# CC27x0 register map
File version: 1.0
CPU: CM4 r0p4, little endian, no MPU, no FPU, VTOR, 3 interrupt priority bits
Registers are 32-bit, read-write, reset 0x0 unless marked. A register's access mark holds for its fields unless they carry their own. Offsets are from the block's base; [hi:lo] are bit positions; {n}, {i} and the like mark numbered series; 'fields as' and 'values as' point back to an identical list.

## CKMD — Clock Controller
Base 0x40001000
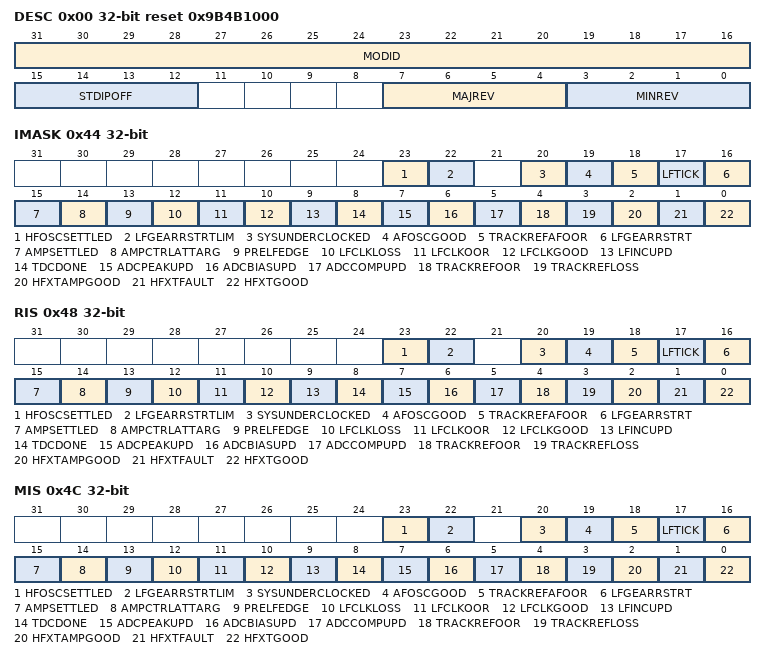
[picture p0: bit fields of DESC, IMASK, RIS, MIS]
0x00 DESC ro reset 0x9B4B1000 — IP Description
  [31:16] MODID — Module identifier
  [15:12] STDIPOFF — Standard IP MMR block offset
  [7:4] MAJREV — Major revision
  [3:0] MINREV — Minor revision
0x44 IMASK — Interrupt mask. This register selects interrupt sources which are allowed to pass from RIS to MIS when the corresponding bit-fields are set to 1.
  [23] HFOSCSETTLED — Indicates that HFOSC has settled, based on LOOPCFG.SETTLED_TARGET and LOOPCFG1.SETTLEIRQ
  [22] LFGEARRSTRTLIM — Indicates that the LFINC filter gearing mechanism has restarted more than LFINCCTL2.GEARRSTRTLIM
  [20] SYSUNDERCLOCKED — Indicates system frequency has been lowered. It will be set only if HFTRACKCTL.UNDERCLK is appropriately configured and HFOSC tracking loop is not running.
  [19] AFOSCGOOD — AFOSC good indication.
  [18] TRACKREFAFOOR — Out-of-range indication from the AFOSC tracking loop. Indicates that the reference clock frequency of AFOSC tracking loop is out-of-range.
  [17] LFTICK — 32kHz TICK to RTC and WDT. Either derived from selected LFCLK or generated from CLKULL in absence of LFCLK.
  [16] LFGEARRSTRT — LFINC filter gearing restart. Indicates that the LFINC filter restarted gearing. Subsequent LFINC estimates may have higher variation.
  [15] AMPSETTLED — HFXT Amplitude compensation - settled Indicates that the amplitude compensation FSM has reached the SETTLED or TCXOMODE state, and the controls configured in HFXTTARG or HFXTDYN are reached.
  [14] AMPCTRLATTARG — HFXT Amplitude compensation - controls at target Indicates that the control values configured in HFXTTARG or HFXTDYN are reached. Applies to Q1CAP, Q2CAP and IREF.
  [13] PRELFEDGE — Pre-LF clock edge detect. Indicates that a positive edge occured on the selected pre-LF clock CLKSEL.PRELFCLK' Can be used by software to confirm that a LF clock source is running and within the expected frequency, before selecting it as the main LF clock source.
  [12] LFCLKLOSS — LF clock is lost. Indicates that no LF clock edge occured for ~49us (~1.6 times nominal period). The system will automatically fall-back to generating LFTICK based on CLKULL, to avoid timing corruption. Note that this signal is NOT related to the analog LF clock-loss detector which can reset the device during STANDBY.
  [11] LFCLKOOR — LF clock period out-of-range. Indicates that a LF clock period was measured to be out-of-range, according to LFQUALCTL.MAXERR.
  [10] LFCLKGOOD — LF clock good. Indicates that the LF clock is good, according to the configuration in LFQUALCTL.
  [9] LFINCUPD — LFINC updated. Indicates that a new LFINC measurement value is available in LFCLKSTAT.LFINC.
  [8] TDCDONE — TDC done event. Indicates that the TDC measurement is done.
  [7] ADCPEAKUPD — HFXT-ADC PEAK measurement update event. Indicates that the HFXT-ADC PEAK measurement is done.
  [6] ADCBIASUPD — HFXT-ADC BIAS measurement update event. Indicates that the HFXT-ADC BIAS measurement is done.
  [5] ADCCOMPUPD — HFXT-ADC comparison update event. Indicates that the HFXT-ADC comparison is done.
  [4] TRACKREFOOR — Out-of-range indication from the tracking loop. Indicates that the selected reference clock frequency of the tracking loop is out-of-range.
  [3] TRACKREFLOSS — Clock loss indication from the tracking loop. Indicates that the selected reference clock of the tracking loop is lost.
  [2] HFXTAMPGOOD — HFXT amplitude good indication.
  [1] HFXTFAULT — HFXT fault indication. Indicates that HFXT did not start correctly, or its frequency is too low. HFXT will not recover from this fault and has to be restarted. This is only a one-time check at HFXT startup.
  [0] HFXTGOOD — HFXT good indication. Indicates that HFXT started correctly. The frequency is not necessarily good enough for radio operation. This is only a one-time check at HFXT startup.
0x48 RIS ro — Raw interrupt flag register
  fields as IMASK
0x4C MIS ro — Masked interrupt flag register
  fields as IMASK
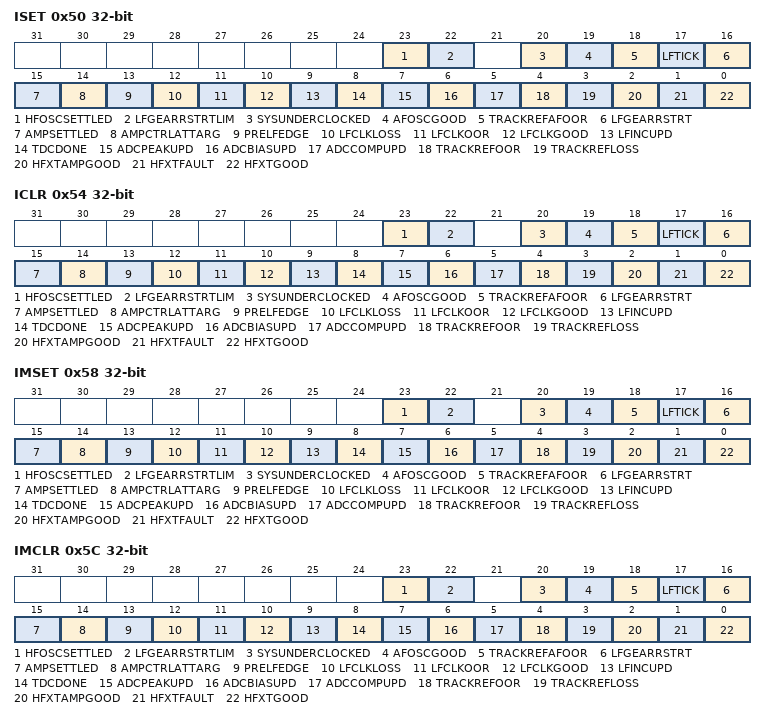
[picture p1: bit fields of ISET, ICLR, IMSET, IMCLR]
0x50 ISET wo — Interrupt flag set register
  fields as IMASK
0x54 ICLR wo — Interrupt flag clear register
  fields as IMASK
0x58 IMSET wo — Interrupt mask set register
  fields as IMASK
0x5C IMCLR wo — Interrupt mask clear register. Writing a 1 to a bit in this register will clear the corresponding IMASK bit.
  fields as IMASK
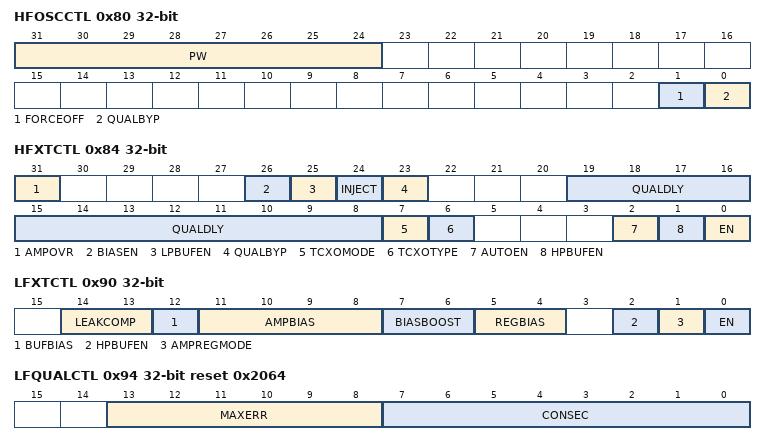
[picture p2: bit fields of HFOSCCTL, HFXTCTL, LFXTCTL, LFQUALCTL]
0x80 HFOSCCTL — Internal. Only to be used through TI provided API.
  [31:24] PW wo — Internal. Only to be used through TI provided API.
  [1] FORCEOFF — Internal. Only to be used through TI provided API.
  [0] QUALBYP — Internal. Only to be used through TI provided API.
0x84 HFXTCTL — High frequency crystal control
  [31] AMPOVR — Internal. Only to be used through TI provided API.
  [26] BIASEN — Internal. Only to be used through TI provided API.
  [25] LPBUFEN — Internal. Only to be used through TI provided API.
  [24] INJECT — Internal. Only to be used through TI provided API.
  [23] QUALBYP — Internal. Only to be used through TI provided API.
  [19:8] QUALDLY — Skip potentially unstable clock cycles after enabling HFXT. Number of cycles skipped is 8*QUALDLY.
  [7] TCXOMODE — Temperature compensated crystal oscillator mode. Set this bit if a TXCO is connected.
  [6] TCXOTYPE — Type of temperature compensated crystal used. Only has effect if TCXOMODE is set.
    1=CMOS (Use with CMOS TCXO); 0=CLIPPEDSINE (Use with clipped-sine TCXO)
  [2] AUTOEN — Internal. Only to be used through TI provided API.
  [1] HPBUFEN — High performance clock buffer enable. This bit controls the clock output for the RF PLL. It is required for radio operation.
  [0] EN — Internal. Only to be used through TI provided API.
0x8C LFOSCCTL — Low frequency oscillator control
  [0] EN — LFOSC enable
0x90 LFXTCTL — Low frequency crystal control
  [14:13] LEAKCOMP — Leakage compensation control
    3=OFF (No leakage compensation); 1=HALF (Half leakage compensation); 0=FULL (Full leakage compensation)
  [12] BUFBIAS — Control the BIAS current of the input amp in LP buffer
    1=MAX (Maximum bias current: 50nA); 0=MIN (Minimum bias current: 25nA)
  [11:8] AMPBIAS — Adjust current mirror ratio into oscillator core. This value is depending on crystal and is set by FW. This field uses a 2's complement encoding.
  [7:6] BIASBOOST — Boost oscillator amplitude This value depends on the crystal and needs to be configured by Firmware.
  [5:4] REGBIAS — Regulation loop bias resistor value This value depends on the crystal and needs to be configured by Firmware.
  [2] HPBUFEN — Control the buffer used. In normal operation, low-power buffer is used in all device modes. The high-performance buffer is only used for test purposes.
  [1] AMPREGMODE — Amplitude regulation mode
    1=LOOPDIS (Amplitude control loop disabled); 0=LOOPEN (Amplitude control loop enabled)
  [0] EN — LFXT enable
0x94 LFQUALCTL reset 0x2064 — Low frequency clock qualification control
  [13:8] MAXERR — Maximum LFCLK period error. Value given in microseconds, 3 integer bits + 3 fractional bits.
  [7:0] CONSEC — Number of consecutive times the LFCLK period error has to be smaller than MAXERR to be considered "good". Setting this value to 0 will bypass clock qualification, and the "good" indicator will always be 1.
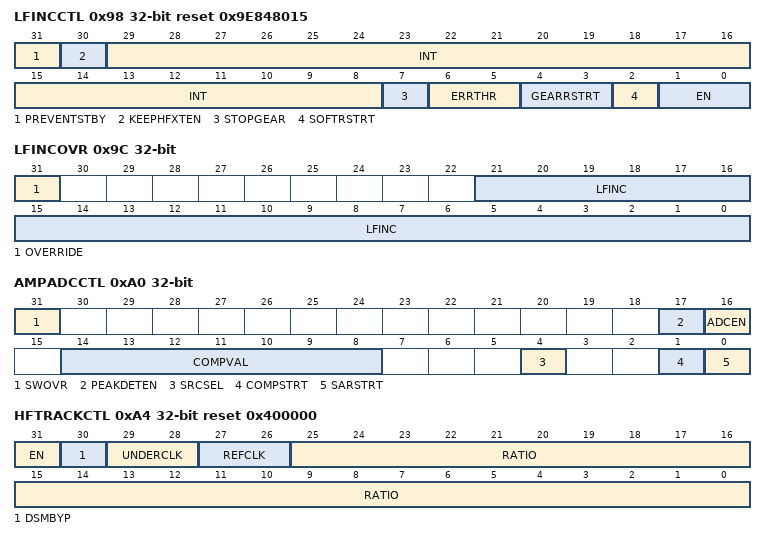
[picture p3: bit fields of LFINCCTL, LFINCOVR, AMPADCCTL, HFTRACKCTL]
0x98 LFINCCTL reset 0x9E848015 — Low frequency time increment control
  [31] PREVENTSTBY — Controls if the LFINC filter prevents STANBY entry until settled.
    1=ON (Enable. Prevent STANDBY entry.); 0=OFF (Disable. Do not prevent STANDBY entry.)
  [30] KEEPHFXTEN — Keeps the HFXT enabled till the LFINC filter settles
    1=EN (Enable. Keep HFXT enabled.); 0=DIS (Disable. Do not keep HFXT enabled.)
  [29:8] INT — Integral part of the LFINC filter. This value is updated by Hardware to reflect the current state of the filter. It can also be written to change the current state.
  [7] STOPGEAR — Controls the final gear of the LFINC filter.
    1=HIGH (The LF filter is considered settled when LFCLKSTAT2.MAINGEAR reads 8 and LFCLKSTAT2.SUBGEAR reads 7. That means the LF filter will take 71 LF periods to settle provided the gear does not restarts.); 0=LOW (The LF filter is considered settled when LFCLKSTAT2.MAINGEAR reads 9 and LFCLKSTAT2.SUBGEAR reads 7. That means the LF filter will take 79 LF periods to settle provided the gear does not restarts.)
  [6:5] ERRTHR — Controls the threshold for gearing restart of the LFINC filter. Only effective if GEARRSTRT is not ONETHR or TWOTHR.
    3=SMALL (Restart gearing on small error. Potentially more false restarts, faster response on small frequency shifts.); 2=MIDSMALL (Middle value towards SMALL.); 1=MIDLARGE (Middle value towards LARGE.); 0=LARGE (Restart gearing on large error. Fewer false restarts, slower response on small frequency shifts.)
  [4:3] GEARRSTRT — Controls gearing restart of the LFINC filter.
    2=TWOTHR (Restart gearing when the error accumulator crosses the threshold twice in a row.); 1=ONETHR (Restart gearing when the error accumulator crosses the threshold once.); 0=NEVER (Never restart gearing. Very stable filter value, but very slow response on frequency changes.)
  [2] SOFTRSTRT — Use a higher gear after re-enabling / wakeup. The filter will require 16-24 LFCLK periods to settle (depending on STOPGEAR), but may respond faster to frequency changes during STANDBY.
    1=ON (Use soft gearing restarts); 0=OFF (Don't use soft gearing restarts)
  [1:0] EN — Enable LFINC filter. Programming with a value of 0x3 will disable the LFINC filter
    2=AUTO (Enable based on HFOS getting settled. HFOSC gets settled after the tracking loop has updated equal to or more than LOOPCFG.SETTLED_TARGET times.); 1=EN (ENABLED); 0=DIS (DISABLED)
0x9C LFINCOVR — Low frequency time increment override control
  [31] OVERRIDE — Override LF increment Use the value provided in LFINC instead of the value calculated by Hardware.
  [21:0] LFINC — LF increment value This value is used when OVERRIDE is set to 1. Otherwise the value is calculated automatically. The current LFINC value can be read from [CKM.LFCLKSTAT.LFINC].
0xA0 AMPADCCTL — Internal. Only to be used through TI provided API.
  [31] SWOVR — Internal. Only to be used through TI provided API.
  [17] PEAKDETEN — Internal. Only to be used through TI provided API.
    1=ENABLE (Internal. Only to be used through TI provided API.); 0=DISABLE (Internal. Only to be used through TI provided API.)
  [16] ADCEN — Internal. Only to be used through TI provided API.
    values as PEAKDETEN
  [14:8] COMPVAL — Internal. Only to be used through TI provided API.
  [4] SRCSEL — Internal. Only to be used through TI provided API.
    1=PEAK (Internal. Only to be used through TI provided API.); 0=BIAS (Internal. Only to be used through TI provided API.)
  [1] COMPSTRT — Internal. Only to be used through TI provided API.
  [0] SARSTRT — Internal. Only to be used through TI provided API.
0xA4 HFTRACKCTL reset 0x400000 — High frequency tracking loop control
  [31] EN — Enable tracking loop.
  [30] DSMBYP — Bypass Delta-Sigma-Modulation of fine trim.
  [29:28] UNDERCLK — When the HFOSC tracking loop is not running, this bitfield can be used to set the condition to automatically lower the HFOSC frequency. This will prevent frequency drift that may lead to SOC instability.
    3=BOTH (Temperature event from Batmon or Timer event); 2=BATMON (Temperature event from Batmon); 1=TIMER (Timer event); 0=DIS (Disable)
  [27:26] REFCLK — Select the reference clock for the tracking loop. Change only while the tracking loop is disabled.
    2=GPI (Select GPI as reference clock.); 1=LRF (Select LRF reference clock.); 0=HFXT (Select HFXT as reference clock.)
  [25:0] RATIO — Reference clock ratio. Ratio format is 2b.24b RATIO = 24MHz / (2*reference-frequency) * 2^24 Commonly used reference clock frequencies are provided as enumerations.
    0x3000000=REF4M (Use for 4MHz reference clock); 0x1800000=REF8M (Use for 8MHz Reference clock); 0x400000=REF48M (Use for 48MHz reference clock)
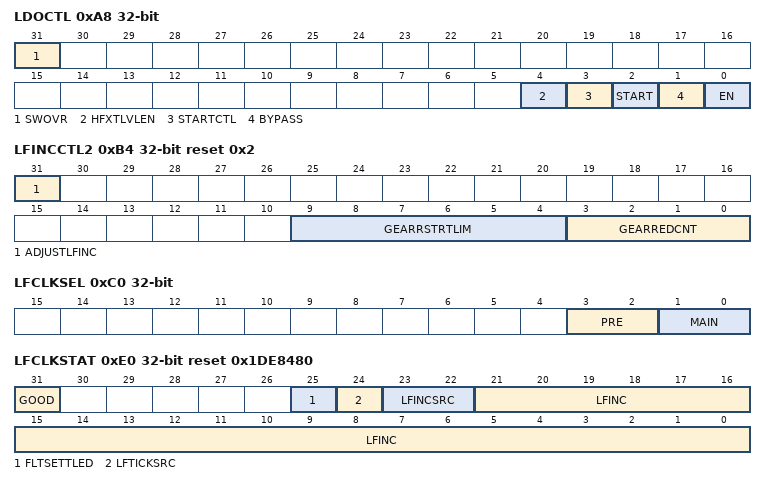
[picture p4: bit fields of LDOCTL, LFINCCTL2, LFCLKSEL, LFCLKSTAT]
0xA8 LDOCTL — Internal. Only to be used through TI provided API.
  [31] SWOVR — Internal. Only to be used through TI provided API.
  [4] HFXTLVLEN — Internal. Only to be used through TI provided API.
  [3] STARTCTL — Internal. Only to be used through TI provided API.
  [2] START — Internal. Only to be used through TI provided API.
  [1] BYPASS — Internal. Only to be used through TI provided API.
  [0] EN — Internal. Only to be used through TI provided API.
0xAC NABIASCTL — Nanoamp-bias control
  [0] EN — Enable nanoamp-bias
0xB0 LFMONCTL — Low-frequency clock-monitor control
  [0] EN — Enable LFMONITOR. Enable only after a LF clock source has been selected, enabled and is stable. If LFMONITOR detects a clock loss, the system will be reset.
0xB4 LFINCCTL2 reset 0x2 — Low frequency time increment control-2
  [31] ADJUSTLFINC — Adjusts LFINC while transitioning from fake to real LF clock if necessary. For the adjustment to happen, tracking loop must be running.
  [9:4] GEARRSTRTLIM — Specifies the number of times gear could be restarted before raising an interrupt. It has no impact on the number of times gear can be reduced. A value of 0 indicates that the interrupt mechanism is disabled
  [3:0] GEARREDCNT — Specifies the number by which gear should be reduced post standby exit
0xC0 LFCLKSEL — Low frequency clock selection
  [3:2] PRE — Select low frequency clock source for the PRELFCLK interrupt. Can be used by Software to confirm that the clock is running and it's frequency is good, before selecting it in MAIN.
    3=EXTLF (External LF clock through GPI.); 2=LFXT (Low frequency crystal oscillator); 1=LFOSC (Low frequency on-chip oscillator); 0=NONE (No clock. Output will be tied low.)
  [1:0] MAIN — Select the main low frequency clock source. If running, this clock will be used to generate LFTICK and as CLKULL during STANDBY. If not running, LFTICK will be generated from HFOSC and STANDBY entry will be prevented.
    3=EXTLF (External LF clock through GPI.); 2=LFXT (Low frequency crystal oscillator); 1=LFOSC (Low frequency on-chip oscillator); 0=FAKE (No LF clock selected. LFTICK will be generated from HFOSC, STANDBY entry will be prevented.)
0xC4 TDCCLKSEL — Internal. Only to be used through TI provided API.
  [2:0] REFCLK
    5=HFXT (Internal. Only to be used through TI provided API.); 4=AFOSC (Internal. Only to be used through TI provided API.); 3=GPI (Internal. Only to be used through TI provided API.); 2=CLKULL (Internal. Only to be used through TI provided API.); 1=CLKSVT (Internal. Only to be used through TI provided API.); 0=NONE (Internal. Only to be used through TI provided API.)
0xC8 ADCCLKSEL — ADC clock selection
  [1:0] SRC — Select ADC clock source Change only while ADC is disabled!
    1=HFXT (48MHz HFXT); 0=CLKSVT (48MHz CLKSVT)
0xE0 LFCLKSTAT ro reset 0x1DE8480 — Low-frequency clock status
  [31] GOOD — Low frequency clock good Note: This is only a coarse frequency check based on LFQUALCTL. The clock may not be accurate enough for timing purposes.
  [25] FLTSETTLED — LFINC filter is running and settled.
  [24] LFTICKSRC — Source of LFTICK.
    1=FAKE (LFTICK generated from CLKULL (LFCLK not available)); 0=LFCLK (LFTICK generated from the selected LFCLK)
  [23:22] LFINCSRC — Source of LFINC used by the RTC. This value depends on LFINCOVR.OVERRIDE, LF clock availability, HF tracking loop status and the device state (ACTIVE/STANDBY).
    3=FAKE (Using FAKE LFTICKs with corresponding LFINC value.); 2=OVERRIDE (Using override value from LFINCOVR.LFINC); 1=AVG (Using filtered / average value. This value is updated by hardware and can be read and updated in LFINCCTL.INT.); 0=MEAS (Using measured value. This value is updated by hardware and can be read from LFINC.)
  [21:0] LFINC — Measured value of LFINC. Given in microseconds with 16 fractional bits. This value is calculated by Hardware. It is the LFCLK period according to CLKULL cycles.
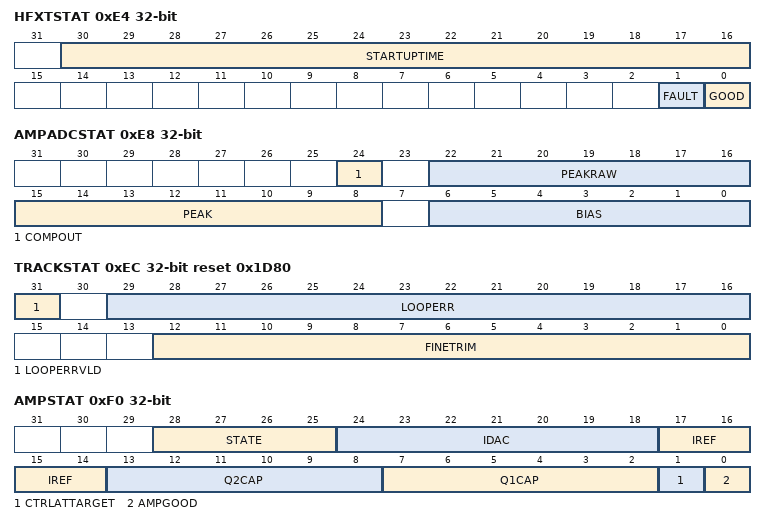
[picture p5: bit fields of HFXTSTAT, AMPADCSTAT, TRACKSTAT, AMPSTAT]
0xE4 HFXTSTAT ro — HFXT status information
  [30:16] STARTUPTIME — HFXT startup time Can be used by software to plan starting HFXT ahead in time. Measured whenever HFXT is enabled in CLKULL periods (24MHz), from HFXTCTL.EN until the clock is good for radio operation (amplitude compensation is settled).
  [1] FAULT — HFXT clock fault Indicates a lower than expected HFXT frequency. HFXT will not recover from this fault, disabling and re-enabling HFXT is required.
  [0] GOOD — HFXT clock available. The frequency is not necessarily good enough for radio operation.
0xE8 AMPADCSTAT ro — Internal. Only to be used through TI provided API.
  [24] COMPOUT — Internal. Only to be used through TI provided API.
  [22:16] PEAKRAW — Internal. Only to be used through TI provided API.
  [15:8] PEAK — Internal. Only to be used through TI provided API.
  [6:0] BIAS — Internal. Only to be used through TI provided API.
0xEC TRACKSTAT reset 0x1D80 — HF tracking loop status information
  [31] LOOPERRVLD ro — Current HFOSC tracking error valid This bit is one if the tracking loop is running and the error value is valid.
  [29:16] LOOPERR ro — Current HFOSC tracking error This field uses the internal fractional representation (sign, 9 integer bits, 4 fractional bits).
  [12:0] FINETRIM ro — Current HFOSC Fine-trim value This field uses the internal fractional representation (sign, 5 integer bits, 7 fractional bits). The actual trim value applied to the oscillator is delta-sigma modulated 6 bits non-signed (inverted sign bit + integer bits).
0xF0 AMPSTAT ro — HFXT Amplitude Compensation Status
  [28:25] STATE — Current AMPCOMP FSM state.
    15=SETTLED (Settled state); 14=UPDATEUP (Amplitude up correction); 12=TXCOMODE (TCXO settled state); 10=SHUTDN0 (First shutdown state); 7=INJWAIT (Post injection settle wait); 6=UPDATEDN (Amplitude down correction); 5=RAMP0 (Initial amplitude ramping with HFXTINIT values); 4=RAMP1 (Transition to HFXTTARG values); 3=INJECT (Injecting HFOSC for fast startup); 2=SHUTDN1 (Second shutdown state); 1=LDOSTART (Starting LDO); 0=IDLE (FSM in idle state)
  [24:18] IDAC — Current IDAC control value.
  [17:14] IREF — Current IREF control value.
  [13:8] Q2CAP — Current Q2CAP control value.
  [7:2] Q1CAP — Current Q1CAP control value.
  [1] CTRLATTARGET — HFXT control values match target values. This applies to IREF, Q1CAP, Q2CAP values.
  [0] AMPGOOD — HFXT amplitude good
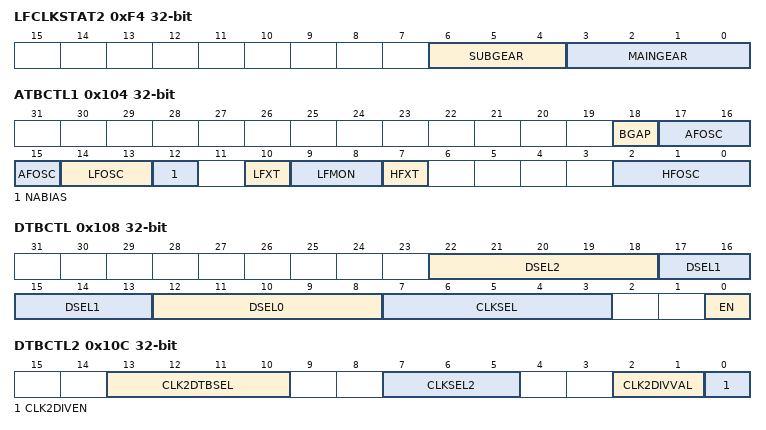
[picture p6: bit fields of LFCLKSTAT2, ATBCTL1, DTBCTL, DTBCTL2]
0xF4 LFCLKSTAT2 ro — Low-frequency clock status-2
  [6:4] SUBGEAR — The value of sub gear in LF filter. It counts from 0 to 7.
  [3:0] MAINGEAR — The value of main gear in LF filter. The main gear increments when the sub gear crosses 7.
0x100 ATBCTL0 — Internal. Only to be used through TI provided API.
  [23:0] SEL
    0x90000=AFOSCTESTCLK (Internal. Only to be used through TI provided API.); 0x70000=LFXTTESTCLK (Internal. Only to be used through TI provided API.); 0x50000=LFOSCTESTCLK (Internal. Only to be used through TI provided API.); 0x30000=HFXTTESTCLK (Internal. Only to be used through TI provided API.); 0x10000=HFOSCTESTCLK (Internal. Only to be used through TI provided API.); 0x4000=AFOSCOUT (Internal. Only to be used through TI provided API.); 0x1000=LFMONVTEST (Internal. Only to be used through TI provided API.); 0x100=HFOSCOUT (Internal. Only to be used through TI provided API.); 128=NABIASITEST (Internal. Only to be used through TI provided API.); 64=ADCDACOUT (Internal. Only to be used through TI provided API.); 32=ADCCOMPIN (Internal. Only to be used through TI provided API.); 16=ADCCOMPOUT (Internal. Only to be used through TI provided API.); 8=LFXTANA (Internal. Only to be used through TI provided API.); 2=VDDCKM (Internal. Only to be used through TI provided API.); 1=HFXTANA (Internal. Only to be used through TI provided API.); 0=OFF (Internal. Only to be used through TI provided API.)
0x104 ATBCTL1 — Internal. Only to be used through TI provided API.
  [18] BGAP — Internal. Only to be used through TI provided API.
  [17:15] AFOSC — Internal. Only to be used through TI provided API.
  [14:13] LFOSC — Internal. Only to be used through TI provided API.
    3=BOTH (Internal. Only to be used through TI provided API.); 2=VDDLOCAL (Internal. Only to be used through TI provided API.); 1=TESTCLK (Internal. Only to be used through TI provided API.); 0=OFF (Internal. Only to be used through TI provided API.)
  [12] NABIAS — Internal. Only to be used through TI provided API.
  [10] LFXT — Internal. Only to be used through TI provided API.
    1=TESTCLK (Internal. Only to be used through TI provided API.); 0=OFF (Internal. Only to be used through TI provided API.)
  [9:8] LFMON — Internal. Only to be used through TI provided API.
    2=TEST2 (Internal. Only to be used through TI provided API.); 1=TEST1 (Internal. Only to be used through TI provided API.); 0=OFF (Internal. Only to be used through TI provided API.)
  [7] HFXT — Internal. Only to be used through TI provided API.
  [2:0] HFOSC — Internal. Only to be used through TI provided API.
0x108 DTBCTL — Digital test bus mux control
  [22:18] DSEL2 — Internal. Only to be used through TI provided API.
  [17:13] DSEL1 — Internal. Only to be used through TI provided API.
  [12:8] DSEL0 — Internal. Only to be used through TI provided API.
  [7:3] CLKSEL — Select clock to output on DTB[0]
    18=HFOSC_DIV2 (HFOSC div by 2 clock); 17=AFOSC (Select AFOSC after qualification); 15=LFXT (Select LFXT); 14=LFOSC (Select LFOSC); 13=HFXT (Select HFXT); 12=HFXTBY8 (Select HFXT divided by 8); 10=HFOSC (Select HFOSC after qualification); 7=LFCLK (Select LFCLK (selected by LFCLKSEL.MAIN)); 4=TRACKREF (Select tracking loop reference clock); 2=CLKADC (Select CLKADC (48 MHz)); 1=CLKSVT (Select CLKSVT (48 MHz)); 0=CLKULL (Select CLKULL (24 MHz during ACTIVE, 32kHz during STANDBY))
  [0] EN — Enable DTB output
0x10C DTBCTL2 — Digital test bus mux control
  [13:10] CLK2DTBSEL — Select a DTB other than DTB0 to route the clock. Value of 0 indicates that clock 2 won't be sent to DTB.
  [7:5] CLKSEL2 — Select the clock that needs to be routed to a DTB other than DTB0
    1=CLKSVT (Select CLKSVT (48 MHz)); 0=CLKULL (Select CLKULL (24 MHz during ACTIVE, 32kHz during STANDBY))
  [2:1] CLK2DIVVAL — These bits are used to configure the divider value.
    3=DIVBY16 (Divide by 16); 2=DIVBY8 (Divide by 8); 1=DIVBY4 (Divide by 4); 0=DIVBY2 (Divide by 2)
  [0] CLK2DIVEN — Enable divider on second clock path
    1=EN (Enable); 0=DIS (Disable)
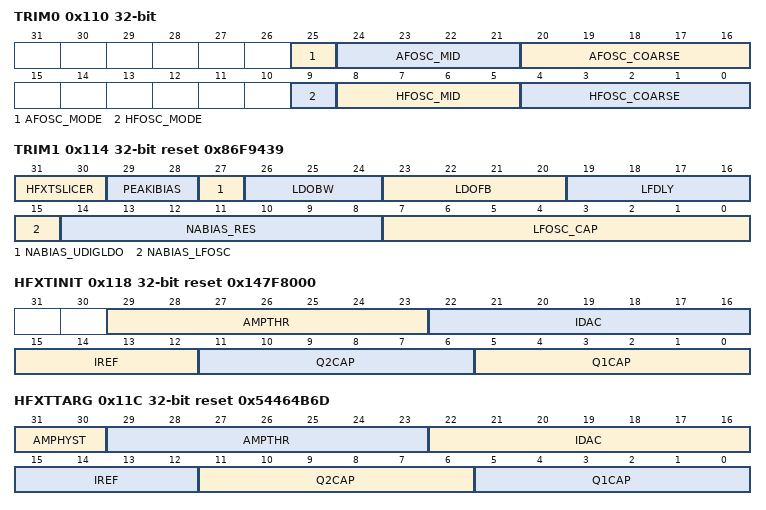
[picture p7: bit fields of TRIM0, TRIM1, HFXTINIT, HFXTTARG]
0x110 TRIM0 — Internal. Only to be used through TI provided API.
  [25] AFOSC_MODE — Internal. Only to be used through TI provided API.
  [24:21] AFOSC_MID — Internal. Only to be used through TI provided API.
  [20:16] AFOSC_COARSE — Internal. Only to be used through TI provided API.
  [9] HFOSC_MODE — Internal. Only to be used through TI provided API.
  [8:5] HFOSC_MID — Internal. Only to be used through TI provided API.
  [4:0] HFOSC_COARSE — Internal. Only to be used through TI provided API.
0x114 TRIM1 reset 0x86F9439 — Internal. Only to be used through TI provided API.
  [31:30] HFXTSLICER — Internal. Only to be used through TI provided API.
  [29:28] PEAKIBIAS — Internal. Only to be used through TI provided API.
  [27] NABIAS_UDIGLDO — Internal. Only to be used through TI provided API.
  [26:24] LDOBW — Internal. Only to be used through TI provided API.
  [23:20] LDOFB — Internal. Only to be used through TI provided API.
  [19:16] LFDLY — Internal. Only to be used through TI provided API.
  [15] NABIAS_LFOSC — Internal. Only to be used through TI provided API.
  [14:8] NABIAS_RES — Internal. Only to be used through TI provided API.
  [7:0] LFOSC_CAP — Internal. Only to be used through TI provided API.
0x118 HFXTINIT reset 0x147F8000 — Initial values for HFXT ramping
  [29:23] AMPTHR — Amplitude threshold during HFXT ramping
  [22:16] IDAC — Initial HFXT IDAC current
  [15:12] IREF — Initial HFXT IREF current
  [11:6] Q2CAP — Initial HFXT Q2 cap trim
    63=CAP63 (Nominal 25C = 1.10E-11 F Strong 25C = 1.00E-11 F Weak 25C = 1.19E-11 F); 62=CAP62 (Nominal 25C = 1.08E-11 F Strong 25C = 9.82E-12 F Weak 25C = 1.17E-11 F); 61=CAP61 (Nominal 25C = 1.06E-11 F Strong 25C = 9.64E-12 F Weak 25C = 1.15E-11 F); 60=CAP60 (Nominal 25C = 1.04E-11 F Strong 25C = 9.45E-12 F Weak 25C = 1.13E-11 F); 59=CAP59 (Nominal 25C = 1.02E-11 F Strong 25C = 9.26E-12 F Weak 25C = 1.11E-11 F); 58=CAP58 (Nominal 25C = 1.00E-11 F Strong 25C = 9.07E-12 F Weak 25C = 1.09E-11 F); 57=CAP57 (Nominal 25C = 9.84E-12 F Strong 25C = 8.89E-12 F Weak 25C = 1.07E-11 F); 56=CAP56 (Nominal 25C = 9.65E-12 F Strong 25C = 8.70E-12 F Weak 25C = 1.04E-11 F); 55=CAP55 (Nominal 25C = 9.46E-12 F Strong 25C = 8.51E-12 F Weak 25C = 1.02E-11 F); 54=CAP54 (Nominal 25C = 9.26E-12 F Strong 25C = 8.32E-12 F Weak 25C = 1.00E-11 F); 53=CAP53 (Nominal 25C = 9.07E-12 F Strong 25C = 8.13E-12 F Weak 25C = 9.81E-12 F); 52=CAP52 (Nominal 25C = 8.88E-12 F Strong 25C = 7.94E-12 F Weak 25C = 9.60E-12 F); 51=CAP51 (Nominal 25C = 8.69E-12 F Strong 25C = 7.76E-12 F Weak 25C = 9.39E-12 F); 50=CAP50 (Nominal 25C = 8.49E-12 F Strong 25C = 7.57E-12 F Weak 25C = 9.18E-12 F); 49=CAP49 (Nominal 25C = 8.30E-12 F Strong 25C = 7.38E-12 F Weak 25C = 8.96E-12 F); 48=CAP48 (Nominal 25C = 8.10E-12 F Strong 25C = 7.18E-12 F Weak 25C = 8.75E-12 F); 47=CAP47 (Nominal 25C = 8.10E-12 F Strong 25C = 7.18E-12 F Weak 25C = 8.75E-12 F); 46=CAP46 (Nominal 25C = 7.97E-12 F Strong 25C = 7.05E-12 F Weak 25C = 8.60E-12 F); 45=CAP45 (Nominal 25C = 7.83E-12 F Strong 25C = 6.91E-12 F Weak 25C = 8.44E-12 F); 44=CAP44 (Nominal 25C = 7.69E-12 F Strong 25C = 6.77E-12 F Weak 25C = 8.29E-12 F); 43=CAP43 (Nominal 25C = 7.55E-12 F Strong 25C = 6.63E-12 F Weak 25C = 8.13E-12 F); 42=CAP42 (Nominal 25C = 7.40E-12 F Strong 25C = 6.49E-12 F Weak 25C = 7.98E-12 F); 41=CAP41 (Nominal 25C = 7.26E-12 F Strong 25C = 6.35E-12 F Weak 25C = 7.82E-12 F); 40=CAP40 (Nominal 25C = 7.12E-12 F Strong 25C = 6.21E-12 F Weak 25C = 7.67E-12 F); 39=CAP39 (Nominal 25C = 6.98E-12 F Strong 25C = 6.06E-12 F Weak 25C = 7.51E-12 F); 38=CAP38 (Nominal 25C = 6.84E-12 F Strong 25C = 5.92E-12 F Weak 25C = 7.35E-12 F); 37=CAP37 (Nominal 25C = 6.69E-12 F Strong 25C = 5.78E-12 F Weak 25C = 7.20E-12 F); 36=CAP36 (Nominal 25C = 6.55E-12 F Strong 25C = 5.63E-12 F Weak 25C = 7.04E-12 F); 35=CAP35 (Nominal 25C = 6.41E-12 F Strong 25C = 5.49E-12 F Weak 25C = 6.88E-12 F); 34=CAP34 (Nominal 25C = 6.26E-12 F Strong 25C = 5.35E-12 F Weak 25C = 6.72E-12 F); 33=CAP33 (Nominal 25C = 6.12E-12 F Strong 25C = 5.20E-12 F Weak 25C = 6.56E-12 F); 32=CAP32 (Nominal 25C = 5.97E-12 F Strong 25C = 5.05E-12 F Weak 25C = 6.40E-12 F); 31=CAP31 (Nominal 25C = 5.72E-12 F Strong 25C = 4.79E-12 F Weak 25C = 6.12E-12 F); 30=CAP30 (Nominal 25C = 5.60E-12 F Strong 25C = 4.67E-12 F Weak 25C = 5.99E-12 F); 29=CAP29 (Nominal 25C = 5.49E-12 F Strong 25C = 4.56E-12 F Weak 25C = 5.87E-12 F); 28=CAP28 (Nominal 25C = 5.37E-12 F Strong 25C = 4.44E-12 F Weak 25C = 5.74E-12 F); 27=CAP27 (Nominal 25C = 5.26E-12 F Strong 25C = 4.32E-12 F Weak 25C = 5.61E-12 F); 26=CAP26 (Nominal 25C = 5.15E-12 F Strong 25C = 4.21E-12 F Weak 25C = 5.49E-12 F); 25=CAP25 (Nominal 25C = 5.03E-12 F Strong 25C = 4.09E-12 F Weak 25C = 5.36E-12 F); 24=CAP24 (Nominal 25C = 4.91E-12 F Strong 25C = 3.97E-12 F Weak 25C = 5.23E-12 F); 23=CAP23 (Nominal 25C = 4.80E-12 F Strong 25C = 3.85E-12 F Weak 25C = 5.10E-12 F); 22=CAP22 (Nominal 25C = 4.68E-12 F Strong 25C = 3.73E-12 F Weak 25C = 4.98E-12 F); 21=CAP21 (Nominal 25C = 4.57E-12 F Strong 25C = 3.60E-12 F Weak 25C = 4.85E-12 F); 20=CAP20 (Nominal 25C = 4.45E-12 F Strong 25C = 3.48E-12 F Weak 25C = 4.72E-12 F); 19=CAP19 (Nominal 25C = 4.33E-12 F Strong 25C = 3.36E-12 F Weak 25C = 4.59E-12 F); 18=CAP18 (Nominal 25C = 4.21E-12 F Strong 25C = 3.23E-12 F Weak 25C = 4.46E-12 F); 17=CAP17 (Nominal 25C = 4.09E-12 F Strong 25C = 3.11E-12 F Weak 25C = 4.33E-12 F); 16=CAP16 (Nominal 25C = 3.97E-12 F Strong 25C = 2.98E-12 F Weak 25C = 4.20E-12 F); 15=CAP15 (Nominal 25C = 3.97E-12 F Strong 25C = 2.98E-12 F Weak 25C = 4.20E-12 F); 14=CAP14 (Nominal 25C = 3.88E-12 F Strong 25C = 2.89E-12 F Weak 25C = 4.10E-12 F); 13=CAP13 (Nominal 25C = 3.79E-12 F Strong 25C = 2.79E-12 F Weak 25C = 4.00E-12 F); 12=CAP12 (Nominal 25C = 3.70E-12 F Strong 25C = 2.69E-12 F Weak 25C = 3.90E-12 F); 11=CAP11 (Nominal 25C = 3.61E-12 F Strong 25C = 2.59E-12 F Weak 25C = 3.80E-12 F); 10=CAP10 (Nominal 25C = 3.51E-12 F Strong 25C = 2.49E-12 F Weak 25C = 3.70E-12 F); 9=CAP9 (Nominal 25C = 3.42E-12 F Strong 25C = 2.39E-12 F Weak 25C = 3.60E-12 F); 8=CAP8 (Nominal 25C = 3.33E-12 F Strong 25C = 2.29E-12 F Weak 25C = 3.50E-12 F); 7=CAP7 (Nominal 25C = 3.23E-12 F Strong 25C = 2.19E-12 F Weak 25C = 3.40E-12 F); 6=CAP6 (Nominal 25C = 3.14E-12 F Strong 25C = 2.09E-12 F Weak 25C = 3.30E-12 F); 5=CAP5 (Nominal 25C = 3.04E-12 F Strong 25C = 1.99E-12 F Weak 25C = 3.19E-12 F); 4=CAP4 (Nominal 25C = 2.95E-12 F Strong 25C = 1.89E-12 F Weak 25C = 3.09E-12 F); 3=CAP3 (Nominal 25C = 2.85E-12 F Strong 25C = 1.79E-12 F Weak 25C = 2.99E-12 F); 2=CAP2 (Nominal 25C = 2.76E-12 F Strong 25C = 1.69E-12 F Weak 25C = 2.89E-12 F); 1=CAP1 (Nominal 25C = 2.66E-12 F Strong 25C = 1.60E-12 F Weak 25C = 2.79E-12 F); 0=CAP0 (Nominal 25C = 2.57E-12 F Strong 25C = 1.50E-12 F Weak 25C = 2.69E-12 F)
  [5:0] Q1CAP — Initial HFXT Q1 cap trim
    values as Q2CAP
0x11C HFXTTARG reset 0x54464B6D — Target values for HFXT ramping
  [31:30] AMPHYST — ADC hysteresis used during IDAC updates. Every AMPCFG1.INTERVAL, IDAC will be regulated - up as long as ADC $lt; AMPTHR - down as long as ADC $gt; AMPTHR+AMPHYST
  [29:23] AMPTHR — Minimum HFXT amplitude
  [22:16] IDAC — Minimum IDAC current
  [15:12] IREF — Target HFXT IREF current
  [11:6] Q2CAP — Target HFXT Q2 cap trim
    values as HFXTINIT.Q2CAP
  [5:0] Q1CAP — Target HFXT Q1 cap trim
    values as HFXTINIT.Q2CAP
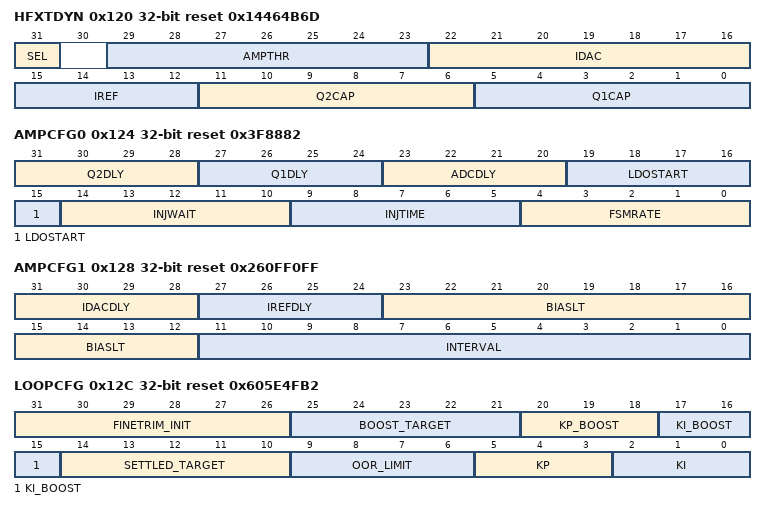
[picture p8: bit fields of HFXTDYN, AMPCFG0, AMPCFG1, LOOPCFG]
0x120 HFXTDYN reset 0x14464B6D — Alternative target values for HFXT configuration Software can change these values to dynamically transition the HFXT configuration while HFXT is running. Set SEL to select the alternative set of target values.
  [31] SEL — Select the dynamic configuration. Amplitude ramping will always happen using the values in HFXTINIT, and HFXTTARG. Afterwards, this bit can be used to select between HFXTTARG and HFXTDYN. Hardware will ensure a smooth transition of analog control signals.
    1=DYNAMIC (Select configuration in CKM.HFXTDYN0 and CKM.HFXTDYN1.); 0=TARGET (Select configuration in CKM.HFXTTARG0 and CKM.HFXTTARG1.)
  [29:23] AMPTHR — Minimum HFXT amplitude
  [22:16] IDAC — Minimum IDAC current
  [15:12] IREF — Target HFXT IREF current
  [11:6] Q2CAP — Target HFXT Q2 cap trim
    values as HFXTINIT.Q2CAP
  [5:0] Q1CAP — Target HFXT Q1 cap trim
    values as HFXTINIT.Q2CAP
0x124 AMPCFG0 reset 0x3F8882 — Amplitude Compensation Configuration 0
  [31:28] Q2DLY — Q2CAP change delay. Number of clock cycles to wait before changing Q2CAP by one step. Clock frequency defined in FSMRATE.
  [27:24] Q1DLY — Q1CAP change delay. Number of clock cycles to wait before changing Q1CAP by one step. Clock frequency defined in FSMRATE.
  [23:20] ADCDLY — ADC and PEAKDET startup time. Number of clock cycles to wait after enabling the PEAKDET and ADC before the first measurement. Clock frequency defined in FSMRATE.
  [19:15] LDOSTART — LDO startup time. Number of clock cycles to bypass the LDO resistors for faster startup. Clock frequency defined in FSMRATE.
  [14:10] INJWAIT — Inject HFOSC for faster HFXT startup. This value specifies the number of clock cycles to wait after injection is done. The clock speed is defined in FSMRATE.
  [9:5] INJTIME — Inject HFOSC for faster HFXT startup. This value specifies the number of clock cycles the injection is enabled. The clock speed is defined in FSMRATE. Set to 0 to disable injection.
  [4:0] FSMRATE — Update rate for the AMPCOMP update rate. Also affects the clock rate for the Amplitude ADC. The update rate is 6MHz / (FSMRATE+1).
    23=_250K (250 kHz); 11=_500K (500 kHz); 5=_1M (1 MHz); 2=_2M (2 MHz); 1=_3M (3 MHz); 0=_6M (6 MHz)
0x128 AMPCFG1 reset 0x260FF0FF — Amplitude Compensation Configuration 1
  [31:28] IDACDLY — IDAC change delay. Time to wait before changing IDAC by one step. This time needs to be long enough for the crystal to settle. The number of clock cycles to wait is IDACDLY$lt;$lt;4 + 15. Clock frequency defined in AMPCFG0.FSMRATE.
  [27:24] IREFDLY — IREF change delay. Number of clock cycles to wait before changing IREF by one step. Clock frequency defined in AMPCFG0.FSMRATE.
  [23:12] BIASLT — Lifetime of the amplitude ADC bias value. This value specifies the number of adjustment intervals, until the ADC bias value has to be measured again. Set to 0 to disable automatic bias measurements.
  [11:0] INTERVAL — Interval for amplitude adjustments. Set to 0 to disable periodic adjustments. This value specifies the number of clock cycles between adjustments. The clock speed is defined in AMPCFG0.FSMRATE.
0x12C LOOPCFG reset 0x605E4FB2 — Configuration Register for the Tracking Loop
  [31:26] FINETRIM_INIT — Initial value for the resistor fine trim
  [25:21] BOOST_TARGET — Error-updates for 4xBOOST_TARGET times using KI_BOOST/KP_BOOST, before using KI/KP. Note: If boost is used for long duration using large values of KI_BOOST $amp; KP_BOOST, the oscillator frequency can reach well above the max frequence limit of the design, causing unexpected behaviour.
  [20:18] KP_BOOST — Proportional loop coefficient during BOOST
  [17:15] KI_BOOST — Integral loop coefficient during BOOST
  [14:10] SETTLED_TARGET — Number of HFOSC tracking loop updates before HFOSC is considered "settled". The tracking loop updates at a rough frequency of (2*Reference frequency/256). If the reference frequency is 48MHz, the loop update frequency comes out to be 375Khz. Internally the MMR is multiplied by 4
  [9:6] OOR_LIMIT — Out-of-range threshold. OOR_LIMIT is compared with absolute value of 5 MSB bits of loop filter error.
  [5:3] KP — Proportional loop coefficient
  [2:0] KI — Integral loop coefficient
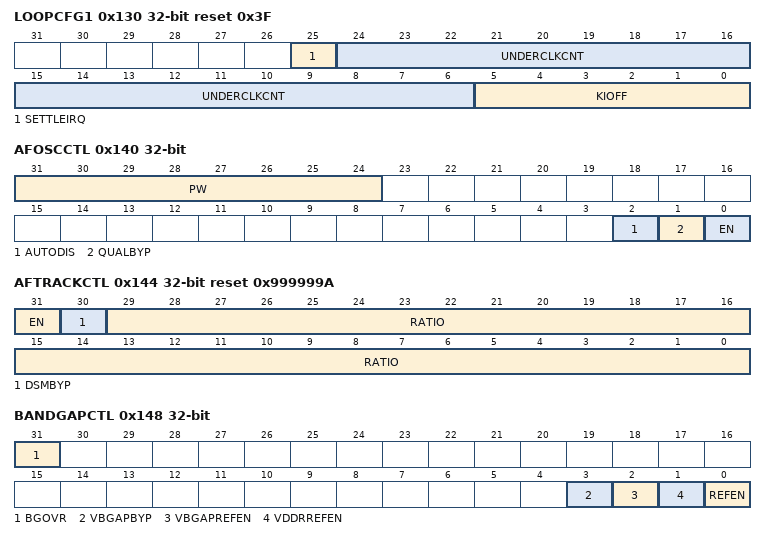
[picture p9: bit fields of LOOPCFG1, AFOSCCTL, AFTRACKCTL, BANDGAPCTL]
0x130 LOOPCFG1 reset 0x3F — Configuration Register for underclocking HFOSC
  [25] SETTLEIRQ — Configuration to enable the interrupt when the HFOSC tracking loop has settled. The interrupt will be based on LOOPCFG.SETTLED_TARGET.
    1=ENABLE (Enable the interrupt to indicate that HFOSC tracking loop has settled.); 0=DISABLE (Disable the interrupt to indicate that HFOSC tracking loop has settled.)
  [24:6] UNDERCLKCNT — Timer to trigger HFOSC underclocking. The timer will run at approximately 32.768 KHz.
  [5:0] KIOFF — Based on HFTRACKCTRL.UNDERCLK configuration, after an event is triggerred, KI of the HFOSC tracking loop will be reduced by this amount.
0x140 AFOSCCTL — Audio frequency oscillator control
  [31:24] PW wo — Password protection for QUALBYP. Write this field to 0xA5 to accept writes to QUALBYP.
  [2] AUTODIS — If set, AFOSC can be disabled by PMCTL upon standby entry. EN bit will be overriden with a value 0 and user has to manually re-enable AFOSC.
  [1] QUALBYP — Clock qualification bypass. AFOSC qualification will skip a fixed number of clock cycles to prevent glitches or frequency overshoots from reaching the system. Setting this bit will bypass the qualification. This bit can be locked in SYS0. If unlocked, it is password protected with PW.
  [0] EN — Enable AFOSC.
0x144 AFTRACKCTL reset 0x999999A — Audio frequency tracking loop control
  [31] EN — Enable tracking loop.
  [30] DSMBYP — Bypass Delta-Sigma-Modulation of fine trim.
  [29:0] RATIO — Ratio. Ratio format is 0b.30b
    0x9B8B578=_79MHZ; 0x999999A=_80MHZ; 0x8EE23B9=_86MHZ; 0x88190AC=_90P288MHZ; 0x7D6343F=_98MHZ
0x148 BANDGAPCTL — Internal. Only to be used through TI provided API.
  [31] BGOVR — Internal. Only to be used through TI provided API.
  [3] VBGAPBYP — Internal. Only to be used through TI provided API.
  [2] VBGAPREFEN — Internal. Only to be used through TI provided API.
  [1] VDDRREFEN — Internal. Only to be used through TI provided API.
  [0] REFEN — Internal. Only to be used through TI provided API.
0x150 AFCLKSEL — Audio clock selection
  [2:0] SRC — Select audio frequency clock source Software should make sure that proper clock is selected before enabling the audio IP.
    4=CLKEXT (External clock); 3=CLKREF (48MHz reference clock (HFXT)); 2=CLKHF (96MHz CLKHF); 1=CLKAF (AFOSC clock); 0=DIS (Clock disabled)
0x154 CANCLKSEL — CAN clock selection
  [1:0] SRC — Select audio frequency clock source Software should make sure that proper clock is selected before enabling the audio IP.
    2=CLKHF (96MHz CLKHF); 1=CLKAF (AFOSC clock); 0=DIS (Clock disabled)
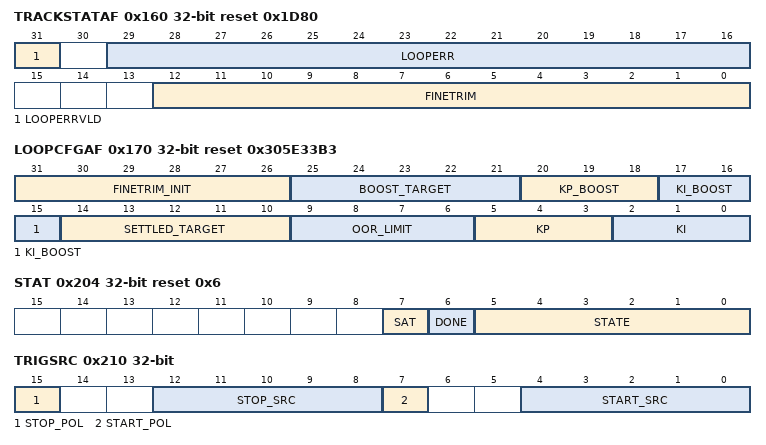
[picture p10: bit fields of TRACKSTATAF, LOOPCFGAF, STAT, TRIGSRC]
0x160 TRACKSTATAF ro reset 0x1D80 — AF tracking loop status information
  [31] LOOPERRVLD — Current AFOSC tracking error valid This bit is one if the tracking loop is running and the error value is valid.
  [29:16] LOOPERR — Current AFOSC tracking error This field uses the internal fractional representation (sign, 9 integer bits, 4 fractional bits). The actual fine trim value of format (sign, 9 integer bits, 30 fractional bits) is saturated to (sign, 9 integer bits, 4 fractional bits).
  [12:0] FINETRIM — Current AFOSC Fine-trim value This field uses the internal fractional representation (sign, 5 integer bits, 7 fractional bits). The actual fine trim value of format (sign, 5 integer bits, 19 fractional bits) is saturated to (sign, 5 integer bits, 7 fractional bits). The actual trim value applied to the oscillator is delta-sigma modulated 6 bits non-signed (inverted sign bit + integer bits).
0x164 TRACKSTATAF1 ro — AF tracking loop status information
  [29:0] LOOPERR — Current AFOSC tracking error This field uses the fractional representation of the actual error(30 fractional bits). The actual error is of format (sign, 9 integer bits, 30 fractional bits).
0x168 TRACKSTATAF2 reset 0x1D80000 — AF tracking loop status information
  [24:0] FINETRIM ro — Current AFOSC Fine-trim value This field uses the internal fractional representation (sign, 5 integer bits, 19 fractional bits). The actual trim value applied to the oscillator is delta-sigma modulated 6 bits non-signed (inverted sign bit + integer bits).
0x170 LOOPCFGAF reset 0x305E33B3 — Configuration Register for the Audio frequency Tracking Loop
  [31:26] FINETRIM_INIT — Initial value for the resistor fine trim
  [25:21] BOOST_TARGET — Number of error-updates using BOOST values, before using KI/KP
  [20:18] KP_BOOST — Proportional loop coefficient during BOOST
  [17:15] KI_BOOST — Integral loop coefficient during BOOST
  [14:10] SETTLED_TARGET — Number of updates before AFOSC is considered "settled"
  [9:6] OOR_LIMIT — Out-of-range threshold. Out-of-range threshold. OOR_LIMIT is compared with absolute value of 5 MSB bits of loop filter error.
  [5:3] KP — Proportional loop coefficient
  [2:0] KI — Integral loop coefficient
0x200 CTL — Control
  [1:0] CMD wo — TDC commands.
    3=ABORT (Force TDC state machine back to IDLE state. Never write this command while [TDC.STAT.STATE] equals CLR_CNT or WAIT_CLR_CNT_DONE.); 2=RUN (Asynchronous counter start. The counter starts to count when the start event is high. To achieve precise edge-to-edge measurements you must ensure that the start event is low for at least 420 ns after you write this command.); 1=RUN_SYNC_START (Synchronous counter start. The counter looks for the opposite edge of the selected start event before it starts to count when the selected edge occurs. This guarantees an edge-triggered start and is recommended for frequency measurements.); 0=CLR_RESULT (Clear [TDC.STAT.SAT], [TDC.STAT.DONE], and [TDC.RESULT.VALUE]. This is not needed as prerequisite for a measurement. Reliable clear is only guaranteed from IDLE state.)
0x204 STAT ro reset 0x6 — Status
  [7] SAT — TDC measurement saturation flag. 0: Conversion has not saturated. 1: Conversion stopped due to saturation. This field is cleared when a new measurement is started or when CLR_RESULT is written to [TDC.CTL.CMD].
  [6] DONE — TDC measurement complete flag. 0: TDC measurement has not yet completed. 1: TDC measurement has completed. This field clears when a new TDC measurement starts or when you write CLR_RESULT to [TDC.CTL.CMD].
  [5:0] STATE — TDC state machine status.
    46=FORCE_STOP (Current state is TDC_FORCESTOP. You wrote ABORT to [TDC.CTL.CMD] to abort the TDC measurement.); 30=START_FALL (Current state is TDC_WAIT_STARTFALL. The fast-counter circuit waits for a falling edge on the start event.); 22=WAIT_CLR_CNT_DONE (Current state is TDC_STATE_WAIT_CLRCNT_DONE. The state machine waits for fast-counter circuit to finish reset.); 15=POR (Current state is TDC_STATE_POR. This is the reset state.); 14=GET_RESULT (Current state is TDC_STATE_GETRESULTS. The state machine copies the counter value from the fast-counter circuit.); 12=WAIT_STOP_CNTDWN (Current state is TDC_STATE_WAIT_STOPCNTDOWN. The fast-counter circuit looks for the stop condition. It will ignore a number of stop events configured in [TDC.TRIGCNTLOAD.CNT].); 8=WAIT_STOP (Current state is TDC_STATE_WAIT_STOP. The state machine waits for the fast-counter circuit to stop.); 7=CLR_CNT (Current state is TDC_STATE_CLRCNT. The fast-counter circuit is reset.); 6=IDLE (Current state is TDC_STATE_IDLE. This is the default state after reset and abortion. State will change when you write [TDC.CTL.CMD] to either RUN_SYNC_START or RUN.); 4=WAIT_START_STOP_CNT_EN (Current state is TDC_STATE_WAIT_STARTSTOPCNTEN. The fast-counter circuit looks for the start condition. The state machine waits for the fast-counter to increment.); 0=WAIT_START (Current state is TDC_STATE_WAIT_START. The fast-counter circuit looks for the start condition. The state machine waits for the fast-counter to increment.)
0x208 RESULT ro reset 0x2 — Result Result of last TDC conversion.
  [31:0] VALUE — TDC conversion result. The result of the TDC conversion is given in number of clock edges of the clock source selected in [IPSPECIFIC.CKM.TDCCLKSEL.REFCLK]. Both rising and falling edges are counted. Note that [TDC.SATCFG.LIMIT] is given in periods, while VALUE is given in edges (periods*2). If TDC counter saturates, VALUE is slightly higher than [TDC.SATCFG.LIMIT]*2, as it takes a non-zero time to stop the measurement. Hence, the maximum value of this field becomes slightly higher than 2^31 (2^30 periods*2) if you configure [TDC.SATCFG.LIMIT] to R30.
0x20C SATCFG — Saturation Configuration
  [4:0] LIMIT — Saturation limit. The flag [TDC.STAT.SAT] is set when the TDC counter saturates. Note that this value is given in periods, while [TDC.RESULT.VALUE] is given in edges (periods*2). Values not enumerated are not supported
    {v}=R{v+9} (TDC conversion saturates and stops after 2^{v+9} periods.) (v=3..21); 0=NONE (No saturation. An additional timer should be used to know if [TDC.RESULT.VALUE] rolled over.)
0x210 TRIGSRC — Trigger Source Select source and polarity for TDC start and stop events. See the Technical Reference Manual for event timing requirements.
  [15] STOP_POL — Polarity of stop source. Change only while [TDC.STAT.STATE] is IDLE.
    1=LOW (TDC conversion stops when low level is detected.); 0=HIGH (TDC conversion stops when high level is detected.)
  [12:8] STOP_SRC — Select stop source from the asynchronous AUX event bus. Change only while [TDC.STAT.STATE] is IDLE.
    31=TDC_PRE (Select TDC Prescaler event which is generated by configuration of TDC.PRECTL.); {v}=DTB{v-5} (Digital testbus bit {v-5}) (v=5..20); 4=GPI (General purpose input signal); 3=LFCLK_DLY (Delayed version of selected LFCLK); 2=LFXT (Low frequency crystal oscillator); 1=LFOSC (Low frequency on-chip oscillator); 0=LFTICK (LFTICK signal going to the RTC)
  [7] START_POL — Polarity of start source. Change only while [TDC.STAT.STATE] is IDLE.
    1=LOW (TDC conversion starts when low level is detected.); 0=HIGH (TDC conversion starts when high level is detected.)
  [4:0] START_SRC — Select start source from the asynchronous AUX event bus. Change only while [TDC.STAT.STATE] is IDLE.
    values as STOP_SRC
0x214 TRIGCNT — Trigger Counter Stop-counter control and status.
  [15:0] CNT — Number of stop events to ignore when [TDC.TRIGCNTCFG.EN] is 1. Read CNT to get the remaining number of stop events to ignore during a TDC measurement. Write CNT to update the remaining number of stop events to ignore during a TDC measurement. The TDC measurement ignores updates of CNT if there are no more stop events left to ignore. When [TDC.TRIGCNTCFG.EN] is 1, [TDC.TRIGCNTLOAD.CNT] is loaded into CNT at the start of the measurement.
0x218 TRIGCNTLOAD — Trigger Counter Load Stop-counter load.
  [15:0] CNT — Number of stop events to ignore when [TDC.TRIGCNTCFG.EN] is 1. To measure frequency of an event source: - Set start event equal to stop event. - Set CNT to number of periods to measure. Both 0 and 1 values measures a single event source period. To measure pulse width of an event source: - Set start event source equal to stop event source. - Select different polarity for start and stop event. - Set CNT to 0. To measure time from the start event to the Nth stop event when N $gt; 1: - Select different start and stop event source. - Set CNT to (N-1). See the Technical Reference Manual for event timing requirements. When [TDC.TRIGCNTCFG.EN] is 1, CNT is loaded into [TDC.TRIGCNT.CNT] at the start of the measurement.
0x21C TRIGCNTCFG — Trigger Counter Configuration Stop-counter configuration.
  [0] EN — Enable stop-counter. 0: Disable stop-counter. 1: Enable stop-counter. Change only while [TDC.STAT.STATE] is IDLE.
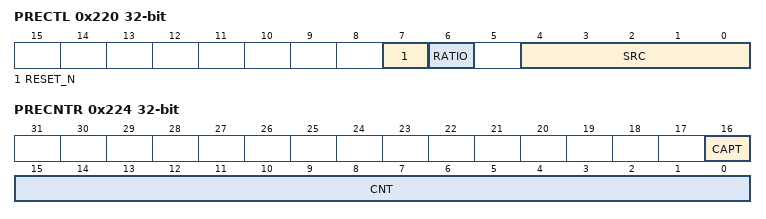
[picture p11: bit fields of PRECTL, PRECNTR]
0x220 PRECTL — Prescaler Control The prescaler can be used to count events that are faster than the bus rate. It can be used to: - count pulses on a specified event from the asynchronous event bus. - prescale a specified event from the asynchronous event bus. To use the prescaler output as an event source in TDC measurements you must set both TRIGSRC.START_SRC and TRIGSRC.STOP_SRC to TDC_PRE. It is recommended to use the prescaler when the signal frequency to measure exceeds 1/10th of the bus rate.
  [7] RESET_N — Prescaler reset. 0: Reset prescaler. 1: Release reset of prescaler. AUX_TDC_PRE event becomes 0 when you reset the prescaler.
  [6] RATIO — Prescaler ratio. This controls how often the TDC_PRE event is generated by the prescaler.
    1=DIV64 (Prescaler divides input by 64. AUX_TDC_PRE event has a rising edge for every 64 rising edges of the input. AUX_TDC_PRE event toggles on every 32nd rising edge of the input.); 0=DIV16 (Prescaler divides input by 16. AUX_TDC_PRE event has a rising edge for every 16 rising edges of the input. AUX_TDC_PRE event toggles on every 8th rising edge of the input.)
  [4:0] SRC — Prescaler event source. Select an event from the asynchronous AUX event bus to connect to the prescaler input. Configure only while RESET_N is 0.
    23=AFOSC (Audio frequency on-chip oscillator); 22=HFXT (High frequency crystal oscillator); 21=HFOSC (High frequency on-chip oscillator); {v}=DTB{v-5} (Digital testbus bit {v-5}) (v=5..20); 4=GPI (General purpose input signal); 3=LFCLK_DLY (Delayed version of selected LFCLK); 2=LFXT (Low frequency crystal oscillator); 1=LFOSC (Low frequency on-chip oscillator); 0=LFTICK (LFTICK signal going to the RTC)
0x224 PRECNTR — Prescaler Counter
  [16] CAPT wo — Prescaler counter capture strobe. Write a 1 to CAPT to capture the value of the 16-bit prescaler counter into CNT. Read CNT to get the captured value.
  [15:0] CNT ro — Prescaler counter value. Write a 1 to CAPT to capture the value of the 16-bit prescaler counter into CNT. Read CNT to get the captured value. The read value gets 1 LSB uncertainty if the event source level rises when you release the reset. The read value gets 1 LSB uncertainty if the event source level rises when you capture the prescaler counter. Please note the following: - The prescaler counter is reset to 3 by [TDC.PRECTL.RESET_N]. - The captured value is 3 when the number of rising edges on prescaler input is less than 3. Otherwise, captured value equals number of event pulses.
0x300 CNT — WDT counter value register
  [31:0] VAL — Counter value. A write to this field immediately starts (or restarts) the counter. It will count down from the written value. If the counter reaches 0, a reset will be generated. A write value of 0 immediately generates a reset. This field is only writable if not locked. See LOCK register. Writing this field will automatically activate the lock. A read returns the current value of the counter.
0x304 TEST — WDT test mode register
  [0] STALLEN — WDT stall enable This field is only writable if not locked. See LOCK register.
    1=EN (ENABLE WDT stops counting while the CPU is stopped by a debugger.); 0=DIS (DISABLE WDT continues counting while the CPU is stopped by a debugger.)
0x308 LOCK reset 0x1 — WDT lock register
  [31:0] STAT — A write with value 0x1ACCE551 unlocks the watchdog registers for write access. A write with any other value locks the watchdog registers for write access. Writing the CNT register will also lock the watchdog registers. A read of this field returns the state of the lock (0=unlocked, 1=locked).
